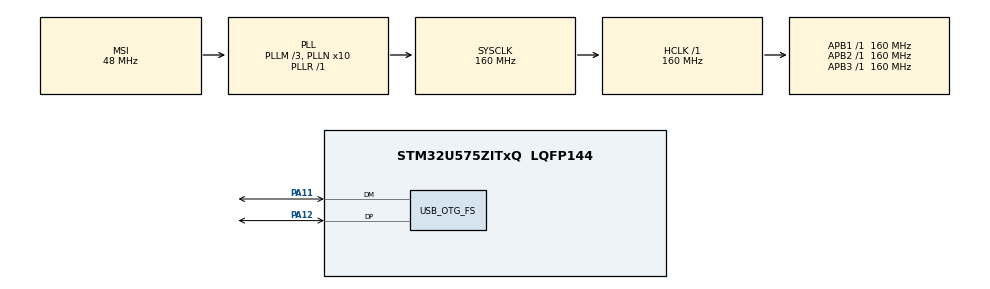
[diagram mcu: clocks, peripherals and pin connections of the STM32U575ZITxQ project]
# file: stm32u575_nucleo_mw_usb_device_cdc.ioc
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CORTEX_M33_NS.userName=CORTEX_M33
Mcu.Family=STM32U5
Mcu.Name=STM32U575ZITxQ
Mcu.Package=LQFP144
NVIC.OTG_FS_IRQn=true\:0\:0\:false\:false\:true\:true\:true\:true
NVIC.PriorityGroup=NVIC_PRIORITYGROUP_4
PA11.Mode=Device_Only
PA11.Signal=USB_OTG_FS_DM
PA12.Mode=Device_Only
PA12.Signal=USB_OTG_FS_DP
PWR.PowerMode=PWR_SMPS_SUPPLY
ProjectManager.HeapSize=0x400
ProjectManager.StackSize=0x800
ProjectManager.TargetToolchain=STM32CubeIDE
RCC.ADCFreq_Value=16000000
RCC.AHBFreq_Value=160000000
RCC.APB1Freq_Value=160000000
RCC.APB1TimFreq_Value=160000000
RCC.APB2Freq_Value=160000000
RCC.APB2TimFreq_Value=160000000
RCC.APB3Freq_Value=160000000
RCC.CortexFreq_Value=160000000
RCC.DACCLockSelectionVirtualString=RCC_DAC1CLKSOURCE_LSI
RCC.EPOD_VALUE=48000000
RCC.HCLKFreq_Value=160000000
RCC.HSE_VALUE=16000000
RCC.HSI48_VALUE=48000000
RCC.HSI_VALUE=16000000
RCC.LSE_VALUE=32768
RCC.LSIDIV_VALUE=32000
RCC.MSIClockRange=RCC_MSIRANGE_0
RCC.MSI_VALUE=48000000
RCC.PLL1R=1
RCC.PLL2FRACN=0
RCC.PLL3FRACN=0
RCC.PLLFRACN=0
RCC.PLLM=3
RCC.PLLN=10
RCC.SYSCLKFreq_VALUE=160000000
RCC.SYSCLKSource=RCC_SYSCLKSOURCE_PLLCLK
RCC.USBFreq_Value=48000000
RCC.VCOOutputFreq_Value=160000000
USB_OTG_FS.VirtualMode=Device_Only
VP_ICACHE_VS_ICACHE.Mode=DirectMappedCache
VP_LPBAMQUEUE_VS_QUEUE.Mode=QUEUEMODE
VP_LPBAM_VS_SIG1.Mode=SmartRun
VP_LPBAM_VS_SIG4.Mode=LPDMA1
VP_PWR_VS_DBSignals.Mode=DisableDeadBatterySignals
VP_PWR_VS_LPOM.Mode=PowerOptimisation
VP_PWR_VS_SECSignals.Mode=Security/Privilege
board=custom

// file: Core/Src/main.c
/* USER CODE BEGIN Header */
/**
  ******************************************************************************
  * @file           : main.c
  * @brief          : Main program body
  ******************************************************************************
  * @attention
  *
  * Copyright (c) 2022 STMicroelectronics.
  * All rights reserved.
  *
  * This software is licensed under terms that can be found in the LICENSE file
  * in the root directory of this software component.
  * If no LICENSE file comes with this software, it is provided AS-IS.
  *
  ******************************************************************************
  */
/* USER CODE END Header */
#include "main.h"

/* USER CODE BEGIN Includes */
#include "usb_device.h"
/* USER CODE END Includes */

PCD_HandleTypeDef hpcd_USB_OTG_FS;

void SystemClock_Config(void);
static void SystemPower_Config(void);
static void MX_GPIO_Init(void);
static void MX_ICACHE_Init(void);
static void MX_USB_OTG_FS_PCD_Init(void);

int main(void)
{

  /* MCU Configuration--------------------------------------------------------*/

  /* Reset of all peripherals, Initializes the Flash interface and the Systick. */
  HAL_Init();

  /* Configure the system clock */
  SystemClock_Config();

  /* Configure the System Power */
  SystemPower_Config();

  /* Initialize all configured peripherals */
  MX_GPIO_Init();
  MX_ICACHE_Init();
  //MX_USB_OTG_FS_PCD_Init();
  /* USER CODE BEGIN 2 */
  MX_USB_Device_Init();
  /* USER CODE END 2 */

  /* Infinite loop */
  while (1)
  {

  }
}

void SystemClock_Config(void)
{
  RCC_OscInitTypeDef RCC_OscInitStruct = {0};
  RCC_ClkInitTypeDef RCC_ClkInitStruct = {0};

  /** Configure the main internal regulator output voltage
  */
  if (HAL_PWREx_ControlVoltageScaling(PWR_REGULATOR_VOLTAGE_SCALE1) != HAL_OK)
  {
    Error_Handler();
  }

  /** Initializes the CPU, AHB and APB buses clocks
  */
  RCC_OscInitStruct.OscillatorType = RCC_OSCILLATORTYPE_HSI48|RCC_OSCILLATORTYPE_MSI;
  RCC_OscInitStruct.HSI48State = RCC_HSI48_ON;
  RCC_OscInitStruct.MSIState = RCC_MSI_ON;
  RCC_OscInitStruct.MSICalibrationValue = RCC_MSICALIBRATION_DEFAULT;
  RCC_OscInitStruct.MSIClockRange = RCC_MSIRANGE_0;
  RCC_OscInitStruct.PLL.PLLState = RCC_PLL_ON;
  RCC_OscInitStruct.PLL.PLLSource = RCC_PLLSOURCE_MSI;
  RCC_OscInitStruct.PLL.PLLMBOOST = RCC_PLLMBOOST_DIV4;
  RCC_OscInitStruct.PLL.PLLM = 3;
  RCC_OscInitStruct.PLL.PLLN = 10;
  RCC_OscInitStruct.PLL.PLLP = 2;
  RCC_OscInitStruct.PLL.PLLQ = 2;
  RCC_OscInitStruct.PLL.PLLR = 1;
  RCC_OscInitStruct.PLL.PLLRGE = RCC_PLLVCIRANGE_1;
  RCC_OscInitStruct.PLL.PLLFRACN = 0;
  if (HAL_RCC_OscConfig(&RCC_OscInitStruct) != HAL_OK)
  {
    Error_Handler();
  }

  /** Initializes the CPU, AHB and APB buses clocks
  */
  RCC_ClkInitStruct.ClockType = RCC_CLOCKTYPE_HCLK|RCC_CLOCKTYPE_SYSCLK
                              |RCC_CLOCKTYPE_PCLK1|RCC_CLOCKTYPE_PCLK2
                              |RCC_CLOCKTYPE_PCLK3;
  RCC_ClkInitStruct.SYSCLKSource = RCC_SYSCLKSOURCE_PLLCLK;
  RCC_ClkInitStruct.AHBCLKDivider = RCC_SYSCLK_DIV1;
  RCC_ClkInitStruct.APB1CLKDivider = RCC_HCLK_DIV1;
  RCC_ClkInitStruct.APB2CLKDivider = RCC_HCLK_DIV1;
  RCC_ClkInitStruct.APB3CLKDivider = RCC_HCLK_DIV1;

  if (HAL_RCC_ClockConfig(&RCC_ClkInitStruct, FLASH_LATENCY_4) != HAL_OK)
  {
    Error_Handler();
  }
}

/**
  * @brief Power Configuration
  * @retval None
  */
static void SystemPower_Config(void)
{

  /*
   * Disable the internal Pull-Up in Dead Battery pins of UCPD peripheral
   */
  HAL_PWREx_DisableUCPDDeadBattery();

  /*
   * Switch to SMPS regulator instead of LDO
   */
  if (HAL_PWREx_ConfigSupply(PWR_SMPS_SUPPLY) != HAL_OK)
  {
    Error_Handler();
  }
}

static void MX_ICACHE_Init(void)
{

  /** Enable instruction cache in 1-way (direct mapped cache)
  */
  if (HAL_ICACHE_ConfigAssociativityMode(ICACHE_1WAY) != HAL_OK)
  {
    Error_Handler();
  }
  if (HAL_ICACHE_Enable() != HAL_OK)
  {
    Error_Handler();
  }

}

static void MX_USB_OTG_FS_PCD_Init(void)
{

  hpcd_USB_OTG_FS.Instance = USB_OTG_FS;
  hpcd_USB_OTG_FS.Init.dev_endpoints = 6;
  hpcd_USB_OTG_FS.Init.phy_itface = PCD_PHY_EMBEDDED;
  hpcd_USB_OTG_FS.Init.Sof_enable = DISABLE;
  hpcd_USB_OTG_FS.Init.low_power_enable = DISABLE;
  hpcd_USB_OTG_FS.Init.lpm_enable = DISABLE;
  hpcd_USB_OTG_FS.Init.battery_charging_enable = DISABLE;
  hpcd_USB_OTG_FS.Init.use_dedicated_ep1 = DISABLE;
  hpcd_USB_OTG_FS.Init.vbus_sensing_enable = DISABLE;
  if (HAL_PCD_Init(&hpcd_USB_OTG_FS) != HAL_OK)
  {
    Error_Handler();
  }

}

static void MX_GPIO_Init(void)
{

  /* GPIO Ports Clock Enable */
  __HAL_RCC_GPIOA_CLK_ENABLE();

}

void Error_Handler(void)
{
  __disable_irq();
  while (1)
  {
  }
}
